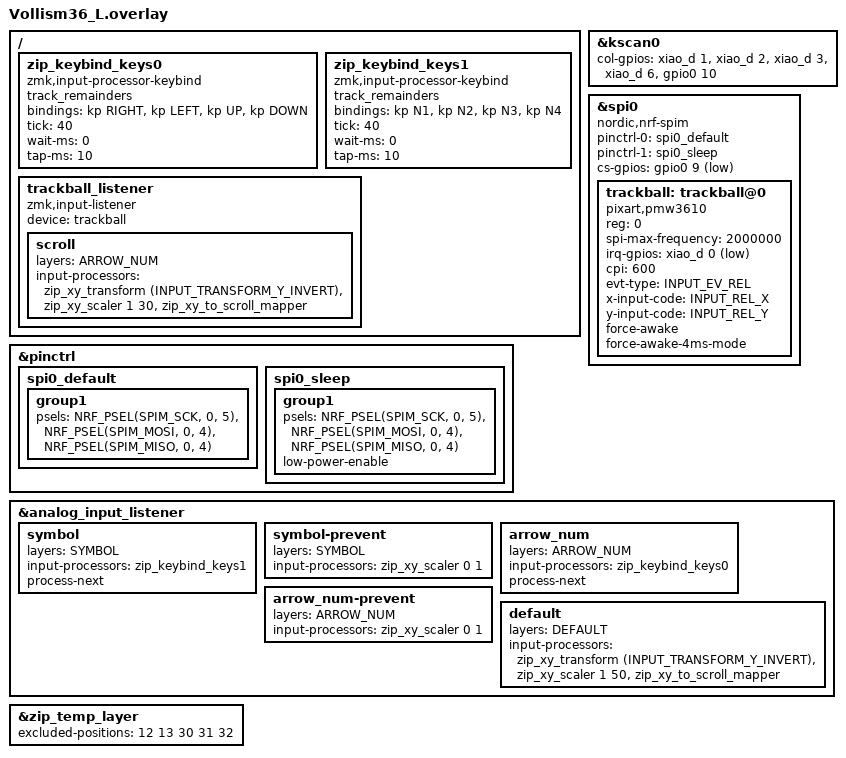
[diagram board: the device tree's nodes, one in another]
#include "Vollism36.dtsi"
#include <input/processors.dtsi>
#include <dt-bindings/zmk/input_transform.h>
#include <zephyr/dt-bindings/input/input-event-codes.h>
#include <dt-bindings/zmk/keys.h>

#define DEFAULT 0
#define QWERTY 1
#define ARROW_NUM 2
#define SYMBOL 3
#define FUNCTION 4
#define MOUSE 5
#define SYSTEM 6


&kscan0 {
        col-gpios
            = <&xiao_d 1 GPIO_ACTIVE_HIGH>
            , <&xiao_d 2 GPIO_ACTIVE_HIGH> 
            , <&xiao_d 3 GPIO_ACTIVE_HIGH> 
            , <&xiao_d 6 GPIO_ACTIVE_HIGH>
            , <&gpio0 10 GPIO_ACTIVE_HIGH>
            ;
};

&pinctrl {
    spi0_default: spi0_default {
        group1 {
            psels = <NRF_PSEL(SPIM_SCK, 0, 5)>,
                <NRF_PSEL(SPIM_MOSI, 0, 4)>,
                <NRF_PSEL(SPIM_MISO, 0, 4)>;
        };
    };

    spi0_sleep: spi0_sleep {
        group1 {
            psels = <NRF_PSEL(SPIM_SCK, 0, 5)>,
                <NRF_PSEL(SPIM_MOSI, 0, 4)>,
                <NRF_PSEL(SPIM_MISO, 0, 4)>;
            low-power-enable;
        };
    };
};

&spi0 {
    status = "okay";
    compatible = "nordic,nrf-spim";
    pinctrl-0 = <&spi0_default>;
    pinctrl-1 = <&spi0_sleep>;
    pinctrl-names = "default", "sleep";
    cs-gpios = <&gpio0 9 GPIO_ACTIVE_LOW>;

    trackball: trackball@0 {
        status = "okay";
        compatible = "pixart,pmw3610";
        reg = <0>;
        spi-max-frequency = <2000000>;
        irq-gpios = <&xiao_d 0 (GPIO_ACTIVE_LOW | GPIO_PULL_UP)>;
        cpi = <600>;
        evt-type = <INPUT_EV_REL>;
        x-input-code = <INPUT_REL_X>;
        y-input-code = <INPUT_REL_Y>;

        force-awake;
        /* keep the sensor awake while ZMK activity state is ACTIVE,
           fallback to normal downshift mode after ZMK goes into IDLE / SLEEP mode.
           thus, the sensor would be a `wakeup-source` */

        force-awake-4ms-mode;
        /* while force-awake is acitvated, enable this mode to force sampling per 
           4ms, where the default sampling rate is 8ms. */
        /* NOTE: apply this mode if you need 250Hz with direct USB connection. */
    };
};

/{
    zip_keybind_keys0: zip_keybind_keys0 {
	        compatible = "zmk,input-processor-keybind";
	        #input-processor-cells = <0>;
		    track_remainders;
	        bindings = <&kp RIGHT>
	                 , <&kp LEFT>
	                 , <&kp UP>
	                 , <&kp DOWN>
                     ;
	        tick = <40>;
	        wait-ms = <0>;
	        tap-ms = <10>;
	        // mode = <0>
	        // threshold = <10>
	        // max_threshold = <200>
	        // max_pending_activations = <10>
    };
	zip_keybind_keys1: zip_keybind_keys1 {
	        compatible = "zmk,input-processor-keybind";
	        #input-processor-cells = <0>;
		    track_remainders;
	        bindings = <&kp N1>
	                 , <&kp N2>
	                 , <&kp N3>
	                 , <&kp N4>
                     ;
	        tick = <40>;
	        wait-ms = <0>;
	        tap-ms = <10>;
	        // mode = <0>
	        // threshold = <10>
	        // max_threshold = <200>
	        // max_pending_activations = <10>
	};

    trackball_listener {
        compatible = "zmk,input-listener";
        device = <&trackball>;
        /*automouse {
                layers = <DEFAULT QWERTY>;
                input-processors = <&zip_temp_layer MOUSE 2000>;
                process-next;
        };*/
        scroll {
                layers = <ARROW_NUM>;
                input-processors = <&zip_xy_transform (INPUT_TRANSFORM_Y_INVERT)>
                                 , <&zip_xy_scaler 1 30>
                                 , <&zip_xy_to_scroll_mapper>;
        };
    };

};

&analog_input_listener {
    status = "okay";
    symbol {
        layers = <SYMBOL>;
        input-processors = <&zip_keybind_keys1>;
        process-next;
    };
    symbol-prevent {
        layers = <SYMBOL>;
        input-processors = <&zip_xy_scaler 0 1>;
    };
    arrow_num {
        layers = <ARROW_NUM>;
        input-processors = <&zip_keybind_keys0>;
        process-next;
    };
    arrow_num-prevent {
        layers = <ARROW_NUM>;
        input-processors = <&zip_xy_scaler 0 1>;
    };
    default {
        layers = <DEFAULT>;
        input-processors = <&zip_xy_transform (INPUT_TRANSFORM_Y_INVERT)>
                         , <&zip_xy_scaler 1 50>
                         , <&zip_xy_to_scroll_mapper>;
    };
};

&zip_temp_layer {
    excluded-positions = <12 13 30 31 32>;
};
